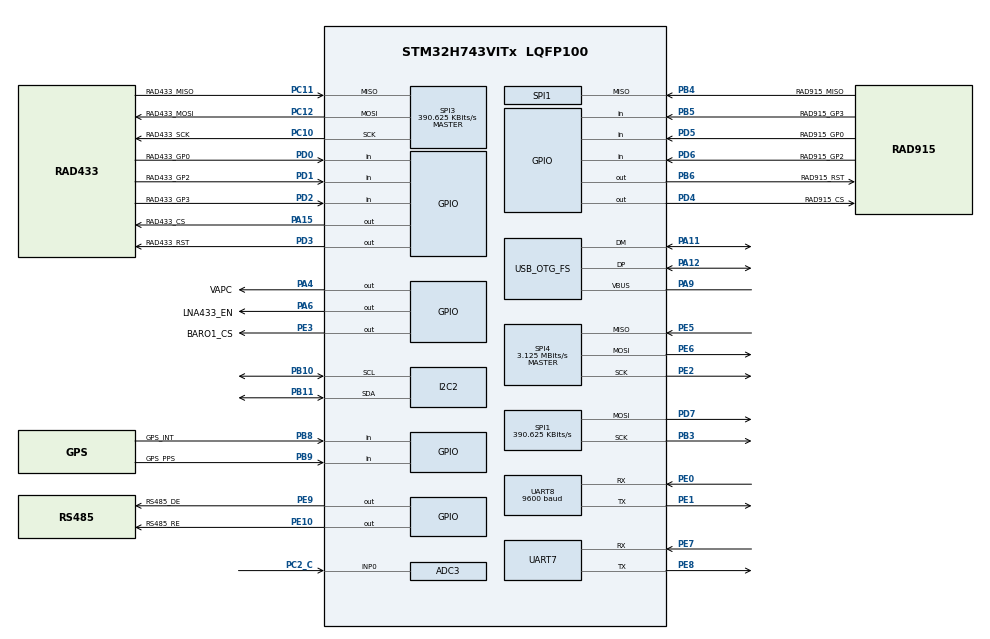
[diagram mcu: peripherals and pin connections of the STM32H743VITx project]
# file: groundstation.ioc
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ADC3.Channel-0\#ChannelRegularConversion=ADC_CHANNEL_0
ADC3.NbrOfConversionFlag=1
ADC3.OffsetNumber-0\#ChannelRegularConversion=ADC_OFFSET_NONE
ADC3.OffsetSignedSaturation-0\#ChannelRegularConversion=DISABLE
ADC3.Rank-0\#ChannelRegularConversion=1
ADC3.SamplingTime-0\#ChannelRegularConversion=ADC_SAMPLETIME_1CYCLE_5
Dma.Request0=UART8_RX
Dma.UART8_RX.0.Direction=DMA_PERIPH_TO_MEMORY
Dma.UART8_RX.0.EventEnable=DISABLE
Dma.UART8_RX.0.FIFOMode=DMA_FIFOMODE_DISABLE
Dma.UART8_RX.0.Instance=DMA1_Stream0
Dma.UART8_RX.0.MemDataAlignment=DMA_MDATAALIGN_BYTE
Dma.UART8_RX.0.MemInc=DMA_MINC_ENABLE
Dma.UART8_RX.0.Mode=DMA_NORMAL
Dma.UART8_RX.0.PeriphDataAlignment=DMA_PDATAALIGN_BYTE
Dma.UART8_RX.0.PeriphInc=DMA_PINC_DISABLE
Dma.UART8_RX.0.Polarity=HAL_DMAMUX_REQ_GEN_RISING
Dma.UART8_RX.0.Priority=DMA_PRIORITY_LOW
Dma.UART8_RX.0.RequestNumber=1
Dma.UART8_RX.0.SignalID=NONE
Dma.UART8_RX.0.SyncEnable=DISABLE
Dma.UART8_RX.0.SyncPolarity=HAL_DMAMUX_SYNC_NO_EVENT
Dma.UART8_RX.0.SyncRequestNumber=1
Dma.UART8_RX.0.SyncSignalID=NONE
I2C2.Timing=0x307075B1
IWDG1.Prescaler=IWDG_PRESCALER_128
IWDG1.Reload=1249
Mcu.Family=STM32H7
Mcu.Name=STM32H743VITx
Mcu.Package=LQFP100
NVIC.DMA1_Stream0_IRQn=true\:0\:0\:false\:false\:true\:false\:true\:true
NVIC.OTG_FS_IRQn=true\:0\:0\:false\:false\:true\:true\:true\:true
NVIC.PriorityGroup=NVIC_PRIORITYGROUP_4
NVIC.UART8_IRQn=true\:0\:0\:false\:false\:true\:true\:true\:true
PA11.Mode=Device_Only
PA11.Signal=USB_OTG_FS_DM
PA12.Mode=Device_Only
PA12.Signal=USB_OTG_FS_DP
PA13\ (JTMS/SWDIO).Mode=Serial_Wire
PA13\ (JTMS/SWDIO).Signal=DEBUG_JTMS-SWDIO
PA14\ (JTCK/SWCLK).Mode=Serial_Wire
PA14\ (JTCK/SWCLK).Signal=DEBUG_JTCK-SWCLK
PA15\ (JTDI).GPIO_Label=RAD433_CS
PA15\ (JTDI).Signal=GPIO_Output
PA4.GPIO_Label=VAPC
PA4.Signal=GPIO_Output
PA6.GPIO_Label=LNA433_EN
PA6.PinAttribute=Free
PA6.Signal=GPIO_Output
PA9.Mode=Activate_VBUS
PA9.Signal=USB_OTG_FS_VBUS
PB10.Mode=I2C
PB10.Signal=I2C2_SCL
PB11.Mode=I2C
PB11.Signal=I2C2_SDA
PB3\ (JTDO/TRACESWO).Mode=Full_Duplex_Master
PB3\ (JTDO/TRACESWO).PinAttribute=Free
PB3\ (JTDO/TRACESWO).Signal=SPI1_SCK
PB4\ (NJTRST).GPIO_Label=RAD915_MISO
PB4\ (NJTRST).Mode=Full_Duplex_Master
PB4\ (NJTRST).Signal=SPI1_MISO
PB5.GPIO_Label=RAD915_GP3
PB5.PinAttribute=Free
PB5.Signal=GPIO_Input
PB6.GPIO_Label=RAD915_RST
PB6.PinAttribute=Free
PB6.Signal=GPIO_Output
PB8.GPIO_Label=GPS_INT
PB8.PinAttribute=Free
PB8.Signal=GPIO_Input
PB9.GPIO_Label=GPS_PPS
PB9.PinAttribute=Free
PB9.Signal=GPIO_Input
PC10.GPIO_Label=RAD433_SCK
PC10.Mode=Full_Duplex_Master
PC10.PinAttribute=Free
PC10.Signal=SPI3_SCK
PC11.GPIO_Label=RAD433_MISO
PC11.Mode=Full_Duplex_Master
PC11.PinAttribute=Free
PC11.Signal=SPI3_MISO
PC12.GPIO_Label=RAD433_MOSI
PC12.Mode=Full_Duplex_Master
PC12.PinAttribute=Free
PC12.Signal=SPI3_MOSI
PC14-OSC32_IN\ (OSC32_IN).Mode=LSE-External-Oscillator
PC14-OSC32_IN\ (OSC32_IN).PinAttribute=Free
PC14-OSC32_IN\ (OSC32_IN).Signal=RCC_OSC32_IN
PC15-OSC32_OUT\ (OSC32_OUT).Mode=LSE-External-Oscillator
PC15-OSC32_OUT\ (OSC32_OUT).PinAttribute=Free
PC15-OSC32_OUT\ (OSC32_OUT).Signal=RCC_OSC32_OUT
PC2_C.Mode=IN0-Single-Ended
PC2_C.Signal=ADC3_INP0
PD0.GPIO_Label=RAD433_GP0
PD0.PinAttribute=Free
PD0.Signal=GPIO_Input
PD1.GPIO_Label=RAD433_GP2
PD1.Signal=GPIO_Input
PD2.GPIO_Label=RAD433_GP3
PD2.PinAttribute=Free
PD2.Signal=GPIO_Input
PD3.GPIO_Label=RAD433_RST
PD3.PinAttribute=Free
PD3.Signal=GPIO_Output
PD4.GPIO_Label=RAD915_CS
PD4.PinAttribute=Free
PD4.Signal=GPIO_Output
PD5.GPIO_Label=RAD915_GP0
PD5.PinAttribute=Free
PD5.Signal=GPIO_Input
PD6.GPIO_Label=RAD915_GP2
PD6.PinAttribute=Free
PD6.Signal=GPIO_Input
PD7.Mode=Full_Duplex_Master
PD7.Signal=SPI1_MOSI
PE0.Mode=Asynchronous
PE0.PinAttribute=Free
PE0.Signal=UART8_RX
PE1.Mode=Asynchronous
PE1.PinAttribute=Free
PE1.Signal=UART8_TX
PE10.GPIO_Label=RS485_RE
PE10.PinAttribute=Free
PE10.Signal=GPIO_Output
PE2.Mode=Full_Duplex_Master
PE2.PinAttribute=Free
PE2.Signal=SPI4_SCK
PE3.GPIO_Label=BARO1_CS
PE3.PinAttribute=Free
PE3.Signal=GPIO_Output
PE5.Mode=Full_Duplex_Master
PE5.PinAttribute=Free
PE5.Signal=SPI4_MISO
PE6.Mode=Full_Duplex_Master
PE6.Signal=SPI4_MOSI
PE7.Mode=Asynchronous
PE7.PinAttribute=Free
PE7.Signal=UART7_RX
PE8.Mode=Asynchronous
PE8.PinAttribute=Free
PE8.Signal=UART7_TX
PE9.GPIO_Label=RS485_DE
PE9.PinAttribute=Free
PE9.Signal=GPIO_Output
PH0-OSC_IN\ (PH0).Mode=HSE-External-Oscillator
PH0-OSC_IN\ (PH0).Signal=RCC_OSC_IN
PH1-OSC_OUT\ (PH1).Mode=HSE-External-Oscillator
PH1-OSC_OUT\ (PH1).Signal=RCC_OSC_OUT
ProjectManager.HeapSize=0x200
ProjectManager.StackSize=0x400
ProjectManager.TargetToolchain=STM32CubeIDE
RCC.ADCCLockSelection=RCC_ADCCLKSOURCE_CLKP
RCC.ADCFreq_Value=64000000
RCC.APB1Freq_Value=120000000
RCC.APB2Freq_Value=120000000
RCC.APB3Freq_Value=120000000
RCC.APB4Freq_Value=120000000
RCC.CortexFreq_Value=480000000
RCC.D1PPRE=RCC_APB3_DIV2
RCC.D2PPRE1=RCC_APB1_DIV2
RCC.D2PPRE2=RCC_APB2_DIV2
RCC.D3PPRE=RCC_APB4_DIV2
RCC.DIVM1=5
RCC.DIVM2=5
RCC.DIVM3=25
RCC.DIVN1=192
RCC.DIVN2=40
RCC.DIVN3=192
RCC.DIVP3=1
RCC.DIVQ3=4
RCC.HCLKFreq_Value=240000000
RCC.HPRE=RCC_HCLK_DIV2
RCC.HSE_VALUE=25000000
RCC.PLL1_VCI_Range-AdvancedSettings=RCC_PLL1VCIRANGE_3
RCC.PLL2FRACN=0
RCC.PLL3FRACN=0
RCC.PLLFRACN=0
RCC.PLLSourceVirtual=RCC_PLLSOURCE_HSE
RCC.SPI123CLockSelection=RCC_SPI123CLKSOURCE_PLL2
RCC.SYSCLKFreq_VALUE=480000000
RCC.SYSCLKSource=RCC_SYSCLKSOURCE_PLLCLK
RCC.Spi45ClockSelection=RCC_SPI45CLKSOURCE_PLL2
RCC.USART234578CLockSelection=RCC_USART234578CLKSOURCE_PLL2
RCC.USBCLockSelection=RCC_USBCLKSOURCE_PLL3
RCC.USBFreq_Value=48000000
SPI1.BaudRatePrescaler=SPI_BAUDRATEPRESCALER_256
SPI1.CalculateBaudRate=390.625 KBits/s
SPI1.DataSize=SPI_DATASIZE_8BIT
SPI1.Direction=SPI_DIRECTION_2LINES
SPI1.Mode=SPI_MODE_MASTER
SPI1.VirtualType=VM_MASTER
SPI3.BaudRatePrescaler=SPI_BAUDRATEPRESCALER_256
SPI3.CalculateBaudRate=390.625 KBits/s
SPI3.DataSize=SPI_DATASIZE_8BIT
SPI3.Direction=SPI_DIRECTION_2LINES
SPI3.Mode=SPI_MODE_MASTER
SPI3.VirtualType=VM_MASTER
SPI4.BaudRatePrescaler=SPI_BAUDRATEPRESCALER_32
SPI4.CalculateBaudRate=3.125 MBits/s
SPI4.DataSize=SPI_DATASIZE_8BIT
SPI4.Direction=SPI_DIRECTION_2LINES
SPI4.Mode=SPI_MODE_MASTER
SPI4.VirtualType=VM_MASTER
TIM1.Channel-PWM\ Generation1\ No\ Output=TIM_CHANNEL_1
UART8.BaudRate=9600
USB_OTG_FS.VirtualMode=Device_Only
VP_IWDG1_VS_IWDG.Mode=IWDG_Activate
VP_TIM1_VS_no_output1.Mode=PWM Generation1 No Output
board=custom

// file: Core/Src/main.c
/* USER CODE BEGIN Header */
/**
 ******************************************************************************
 * @file           : main.c
 * @brief          : Main program body
 ******************************************************************************
 * @attention
 *
 * <h2><center>&copy; Copyright (c) 2022 STMicroelectronics.
 * All rights reserved.</center></h2>
 *
 * This software component is licensed by ST under BSD 3-Clause license,
 * the "License"; You may not use this file except in compliance with theWill it
 *go too fast? License. You may obtain a copy of the License at:
 *                        opensource.org/licenses/BSD-3-Clause
 *
 ******************************************************************************
 */
/* USER CODE END Header */
#include "main.h"
#include "adc.h"
#include "dma.h"
#include "i2c.h"
#include "iwdg.h"
#include "spi.h"
#include "tim.h"
#include "usart.h"
#include "usb_device.h"
#include "gpio.h"

/* USER CODE BEGIN PD */
void groundstation_main();
/* USER CODE END PD */

void SystemClock_Config(void);
void PeriphCommonClock_Config(void);

int main(void)
{

  /* MCU Configuration--------------------------------------------------------*/

  /* Reset of all peripherals, Initializes the Flash interface and the Systick. */
  HAL_Init();

  /* Configure the system clock */
  SystemClock_Config();

/* Configure the peripherals common clocks */
  PeriphCommonClock_Config();

  /* Initialize all configured peripherals */
  MX_GPIO_Init();
  MX_DMA_Init();
  MX_SPI1_Init();
  MX_SPI3_Init();
  MX_SPI4_Init();
  MX_UART7_Init();
  MX_UART8_Init();
  MX_USB_DEVICE_Init();
  MX_TIM1_Init();
  MX_ADC3_Init();
  MX_I2C2_Init();
  MX_IWDG1_Init();
  /* USER CODE BEGIN 2 */
  groundstation_main();

  /* USER CODE END 2 */

  /* Infinite loop */
  while (1) {

  }
}

void SystemClock_Config(void)
{
  RCC_OscInitTypeDef RCC_OscInitStruct = {0};
  RCC_ClkInitTypeDef RCC_ClkInitStruct = {0};

  /** Supply configuration update enable
  */
  HAL_PWREx_ConfigSupply(PWR_LDO_SUPPLY);
  /** Configure the main internal regulator output voltage
  */
  __HAL_PWR_VOLTAGESCALING_CONFIG(PWR_REGULATOR_VOLTAGE_SCALE0);

  while(!__HAL_PWR_GET_FLAG(PWR_FLAG_VOSRDY)) {}
  /** Macro to configure the PLL clock source
  */
  __HAL_RCC_PLL_PLLSOURCE_CONFIG(RCC_PLLSOURCE_HSE);
  /** Initializes the RCC Oscillators according to the specified parameters
  * in the RCC_OscInitTypeDef structure.
  */
  RCC_OscInitStruct.OscillatorType = RCC_OSCILLATORTYPE_HSI|RCC_OSCILLATORTYPE_LSI
                              |RCC_OSCILLATORTYPE_HSE;
  RCC_OscInitStruct.HSEState = RCC_HSE_ON;
  RCC_OscInitStruct.HSIState = RCC_HSI_DIV1;
  RCC_OscInitStruct.HSICalibrationValue = RCC_HSICALIBRATION_DEFAULT;
  RCC_OscInitStruct.LSIState = RCC_LSI_ON;
  RCC_OscInitStruct.PLL.PLLState = RCC_PLL_ON;
  RCC_OscInitStruct.PLL.PLLSource = RCC_PLLSOURCE_HSE;
  RCC_OscInitStruct.PLL.PLLM = 5;
  RCC_OscInitStruct.PLL.PLLN = 192;
  RCC_OscInitStruct.PLL.PLLP = 2;
  RCC_OscInitStruct.PLL.PLLQ = 2;
  RCC_OscInitStruct.PLL.PLLR = 2;
  RCC_OscInitStruct.PLL.PLLRGE = RCC_PLL1VCIRANGE_2;
  RCC_OscInitStruct.PLL.PLLVCOSEL = RCC_PLL1VCOWIDE;
  RCC_OscInitStruct.PLL.PLLFRACN = 0;
  if (HAL_RCC_OscConfig(&RCC_OscInitStruct) != HAL_OK)
  {
    Error_Handler();
  }
  /** Initializes the CPU, AHB and APB buses clocks
  */
  RCC_ClkInitStruct.ClockType = RCC_CLOCKTYPE_HCLK|RCC_CLOCKTYPE_SYSCLK
                              |RCC_CLOCKTYPE_PCLK1|RCC_CLOCKTYPE_PCLK2
                              |RCC_CLOCKTYPE_D3PCLK1|RCC_CLOCKTYPE_D1PCLK1;
  RCC_ClkInitStruct.SYSCLKSource = RCC_SYSCLKSOURCE_PLLCLK;
  RCC_ClkInitStruct.SYSCLKDivider = RCC_SYSCLK_DIV1;
  RCC_ClkInitStruct.AHBCLKDivider = RCC_HCLK_DIV2;
  RCC_ClkInitStruct.APB3CLKDivider = RCC_APB3_DIV2;
  RCC_ClkInitStruct.APB1CLKDivider = RCC_APB1_DIV2;
  RCC_ClkInitStruct.APB2CLKDivider = RCC_APB2_DIV2;
  RCC_ClkInitStruct.APB4CLKDivider = RCC_APB4_DIV2;

  if (HAL_RCC_ClockConfig(&RCC_ClkInitStruct, FLASH_LATENCY_4) != HAL_OK)
  {
    Error_Handler();
  }
}

void PeriphCommonClock_Config(void)
{
  RCC_PeriphCLKInitTypeDef PeriphClkInitStruct = {0};

  /** Initializes the peripherals clock
  */
  PeriphClkInitStruct.PeriphClockSelection = RCC_PERIPHCLK_USB|RCC_PERIPHCLK_SPI3
                              |RCC_PERIPHCLK_SPI1|RCC_PERIPHCLK_SPI4
                              |RCC_PERIPHCLK_UART8|RCC_PERIPHCLK_UART7
                              |RCC_PERIPHCLK_CKPER;
  PeriphClkInitStruct.PLL2.PLL2M = 5;
  PeriphClkInitStruct.PLL2.PLL2N = 40;
  PeriphClkInitStruct.PLL2.PLL2P = 2;
  PeriphClkInitStruct.PLL2.PLL2Q = 2;
  PeriphClkInitStruct.PLL2.PLL2R = 2;
  PeriphClkInitStruct.PLL2.PLL2RGE = RCC_PLL2VCIRANGE_2;
  PeriphClkInitStruct.PLL2.PLL2VCOSEL = RCC_PLL2VCOWIDE;
  PeriphClkInitStruct.PLL2.PLL2FRACN = 0;
  PeriphClkInitStruct.PLL3.PLL3M = 25;
  PeriphClkInitStruct.PLL3.PLL3N = 192;
  PeriphClkInitStruct.PLL3.PLL3P = 1;
  PeriphClkInitStruct.PLL3.PLL3Q = 4;
  PeriphClkInitStruct.PLL3.PLL3R = 2;
  PeriphClkInitStruct.PLL3.PLL3RGE = RCC_PLL3VCIRANGE_0;
  PeriphClkInitStruct.PLL3.PLL3VCOSEL = RCC_PLL3VCOWIDE;
  PeriphClkInitStruct.PLL3.PLL3FRACN = 0;
  PeriphClkInitStruct.CkperClockSelection = RCC_CLKPSOURCE_HSI;
  PeriphClkInitStruct.Spi123ClockSelection = RCC_SPI123CLKSOURCE_PLL2;
  PeriphClkInitStruct.Spi45ClockSelection = RCC_SPI45CLKSOURCE_PLL2;
  PeriphClkInitStruct.Usart234578ClockSelection = RCC_USART234578CLKSOURCE_PLL2;
  PeriphClkInitStruct.UsbClockSelection = RCC_USBCLKSOURCE_PLL3;
  if (HAL_RCCEx_PeriphCLKConfig(&PeriphClkInitStruct) != HAL_OK)
  {
    Error_Handler();
  }
}

void Error_Handler(void)
{
  __disable_irq();
  while (1) {
  }
}

#ifdef  USE_FULL_ASSERT
/**
  * @brief  Reports the name of the source file and the source line number
  *         where the assert_param error has occurred.
  * @param  file: pointer to the source file name
  * @param  line: assert_param error line source number
  * @retval None
  */
void assert_failed(uint8_t *file, uint32_t line)
{
  /* USER CODE BEGIN 6 */
  /* User can add his own implementation to report the file name and line
     number, ex: printf("Wrong parameters value: file %s on line %d\r\n", file,
     line) */
  /* USER CODE END 6 */
}
#endif /* USE_FULL_ASSERT */

/************************ (C) COPYRIGHT STMicroelectronics *****END OF FILE****/
